# f280015x_mem_cfg_regs register map
Vendor: Texas Instruments
Peripheral module from a debugger description file (folder C2000).
Address unit: 16 bits
Registers are 32-bit, read-write, no defined reset value unless marked. A register's access mark holds for its fields unless they carry their own. Offsets are as the file gives them; lines under a group give offsets from that group; [hi:lo] are bit positions; {n}, {i} and the like mark numbered series; 'fields as' and 'values as' point back to an identical list; <NAME> marks a mode.

## MEM_CFG_REGS — MEM CFG Registers
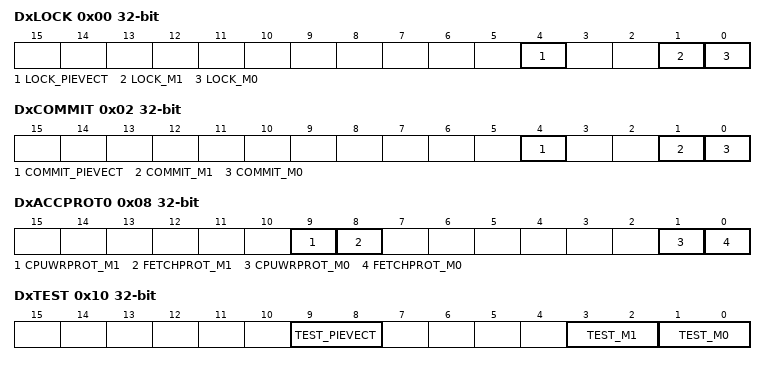
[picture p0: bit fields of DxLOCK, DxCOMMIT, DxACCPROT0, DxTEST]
0x00 DxLOCK — Dedicated RAM Config Lock Register
  [4] LOCK_PIEVECT — PIEVECT RAM Lock bits
  [1] LOCK_M1 — M1 RAM Lock bits
  [0] LOCK_M0 — M0 RAM Lock bits
0x02 DxCOMMIT — Dedicated RAM Config Lock Commit Register
  [4] COMMIT_PIEVECT — PIEVECT RAM Permanent Lock bits
  [1] COMMIT_M1 — M1 RAM Permanent Lock bits
  [0] COMMIT_M0 — M0 RAM Permanent Lock bits
0x08 DxACCPROT0 — Dedicated RAM Config Register
  [9] CPUWRPROT_M1 — CPU WR Protection For M1 RAM
  [8] FETCHPROT_M1 — Fetch Protection For M1 RAM
  [1] CPUWRPROT_M0 — CPU WR Protection For M0 RAM
  [0] FETCHPROT_M0 — Fetch Protection For M0 RAM
0x0A DxACCPROT1 — Dedicated RAM Config Register
  [1] CPUWRPROT_PIEVECT — CPU WR Protection For PIEVECT RAM
0x10 DxTEST — Dedicated RAM TEST Register
  [9:8] TEST_PIEVECT — Selects the different modes for PIEVECT RAM
  [3:2] TEST_M1 — Selects the different modes for M1 RAM
  [1:0] TEST_M0 — Selects the different modes for M0 RAM
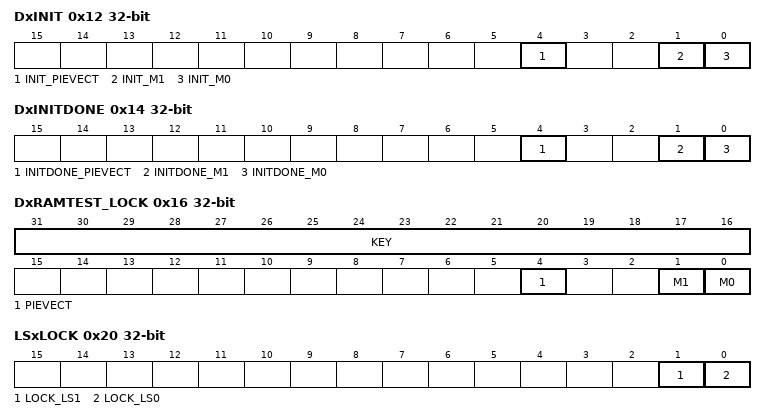
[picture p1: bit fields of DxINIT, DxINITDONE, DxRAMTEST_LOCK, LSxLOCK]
0x12 DxINIT — Dedicated RAM Init Register
  [4] INIT_PIEVECT — RAM Initialization control for PIEVECT RAM.
  [1] INIT_M1 — RAM Initialization control for M1 RAM.
  [0] INIT_M0 — RAM Initialization control for M0 RAM.
0x14 DxINITDONE ro — Dedicated RAM InitDone Status Register
  [4] INITDONE_PIEVECT — RAM Initialization status for PIEVECT RAM.
  [1] INITDONE_M1 — RAM Initialization status for M1 RAM.
  [0] INITDONE_M0 — RAM Initialization status for M0 RAM.
0x16 DxRAMTEST_LOCK — Lock register to Dx RAM TEST registers
  [31:16] KEY — Key for writing DxRAMTEST_LOCK
  [4] PIEVECT — DxTEST.TEST_PIEVECT LOCK
  [1] M1 — DxTEST.TEST_M1 LOCK
  [0] M0 — DxTEST.TEST_M0 LOCK
0x20 LSxLOCK — Local Shared RAM Config Lock Register
  [1] LOCK_LS1 — LS1 RAM Lock bits
  [0] LOCK_LS0 — LS0 RAM Lock bits
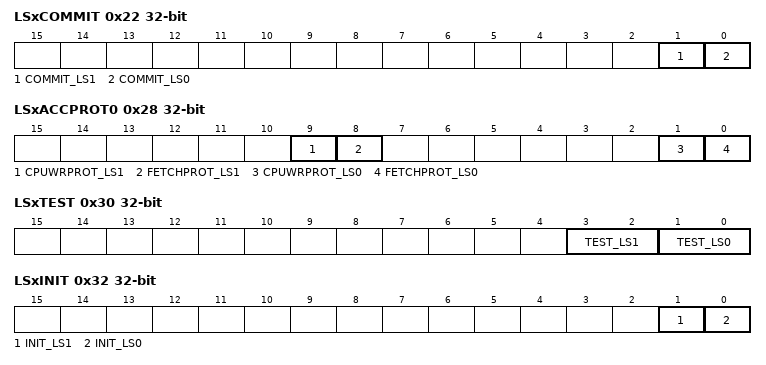
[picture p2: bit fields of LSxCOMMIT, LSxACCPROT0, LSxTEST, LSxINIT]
0x22 LSxCOMMIT — Local Shared RAM Config Lock Commit Register
  [1] COMMIT_LS1 — LS1 RAM Permanent Lock bits
  [0] COMMIT_LS0 — LS0 RAM Permanent Lock bits
0x28 LSxACCPROT0 — Local Shared RAM Config Register 0
  [9] CPUWRPROT_LS1 — CPU WR Protection For LS1 RAM
  [8] FETCHPROT_LS1 — Fetch Protection For LS1 RAM
  [1] CPUWRPROT_LS0 — CPU WR Protection For LS0 RAM
  [0] FETCHPROT_LS0 — Fetch Protection For LS0 RAM
0x30 LSxTEST — Local Shared RAM TEST Register
  [3:2] TEST_LS1 — Selects the different modes for LS1 RAM
  [1:0] TEST_LS0 — Selects the different modes for LS0 RAM
0x32 LSxINIT — Local Shared RAM Init Register
  [1] INIT_LS1 — RAM Initialization control for LS1 RAM.
  [0] INIT_LS0 — RAM Initialization control for LS0 RAM.
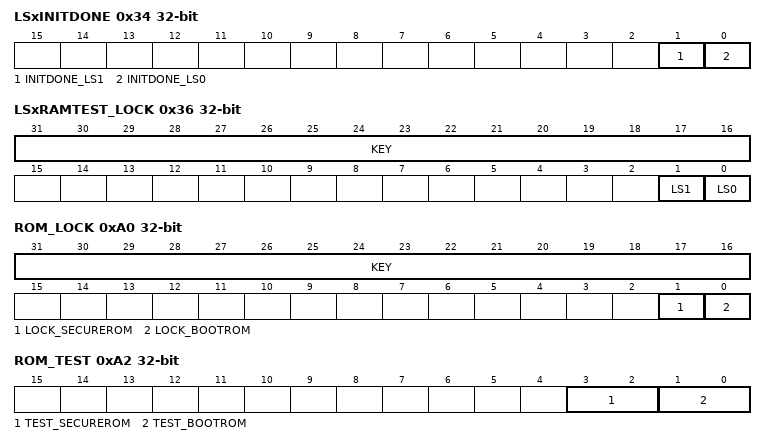
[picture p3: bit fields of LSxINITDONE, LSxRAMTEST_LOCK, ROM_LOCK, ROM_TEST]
0x34 LSxINITDONE ro — Local Shared RAM InitDone Status Register
  [1] INITDONE_LS1 — RAM Initialization status for LS1 RAM.
  [0] INITDONE_LS0 — RAM Initialization status for LS0 RAM.
0x36 LSxRAMTEST_LOCK — Lock register to LSx RAM TEST registers
  [31:16] KEY — KEY to enable write to lock
  [1] LS1 — LSxTEST.TEST_LS1 LOCK
  [0] LS0 — LSxTEST.TEST_LS0 LOCK
0xA0 ROM_LOCK — ROM Config Lock Register
  [31:16] KEY — Key for writing ROM LOCK
  [1] LOCK_SECUREROM — SECUREROM Lock bits
  [0] LOCK_BOOTROM — BOOTROM Lock bits
0xA2 ROM_TEST
  [3:2] TEST_SECUREROM — Selects the different modes for SECUREROM
  [1:0] TEST_BOOTROM — Selects the different modes for BOOTROM
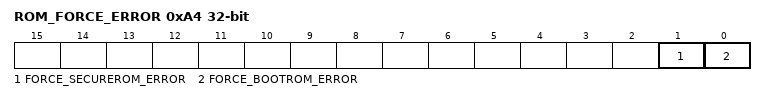
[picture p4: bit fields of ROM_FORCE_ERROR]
0xA4 ROM_FORCE_ERROR
  [1] FORCE_SECUREROM_ERROR — Force SECUREROM Parity Error
  [0] FORCE_BOOTROM_ERROR — Force Bootrom Parity Error
